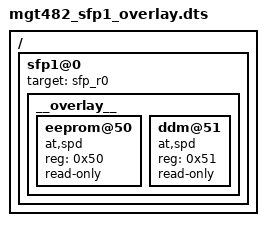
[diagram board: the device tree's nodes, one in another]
/dts-v1/;
/plugin/;	/* allow undefined label references and record them */
/ {					
	sfp1@0 {
		target = <&sfp_r0>;
		__overlay__ {
			#address-cells = <1>;
			#size-cells = <0>;
			eeprom@50 {
				compatible = "at,spd";								
				reg = <0x50>;
				read-only;
				status="okay";
			};
			ddm@51 {
				compatible = "at,spd";
				reg = <0x51>;
				read-only;
				status="okay";
			};			
		};					
	};
};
